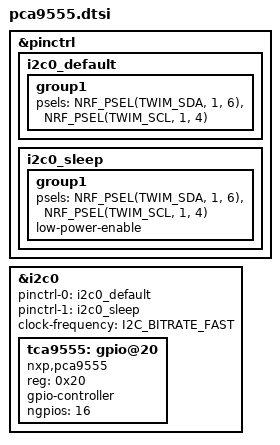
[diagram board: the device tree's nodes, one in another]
#define INPUT_EV_KEY 0x01               /**< Key event */
#define INPUT_EV_REL 0x02               /**< Relative coordinate event */
#define INPUT_EV_ABS 0x03               /**< Absolute coordinate event */
#define INPUT_EV_MSC 0x04               /**< Miscellaneous event */
#define INPUT_EV_VENDOR_START 0xf0      /**< Vendor specific event start */
#define INPUT_EV_VENDOR_STOP 0xff       /**< Vendor specific event stop */

#define INPUT_REL_X 0x00                /**< Relative X coordinate */
#define INPUT_REL_Y 0x01                /**< Relative Y coordinate */
#define INPUT_REL_WHEEL 0x08            /**< Relative wheel coordinate */
#define INPUT_REL_HWHEEL 0x06           /**< Relative horizontal wheel coordinate */
#define INPUT_REL_MISC 0x09             /**< Relative misc coordinate */

&pinctrl {
    i2c0_default: i2c0_default {
        group1 {
            psels =
                <NRF_PSEL(TWIM_SDA, 1, 6)>,
                <NRF_PSEL(TWIM_SCL, 1, 4)>;
        };
    };


    i2c0_sleep: i2c0_sleep {
        group1 {
            psels = <NRF_PSEL(TWIM_SDA, 1, 6)>,
                    <NRF_PSEL(TWIM_SCL, 1, 4)>;
            low-power-enable;
        };
    };
};


&i2c0 {
    status = "okay";

    pinctrl-0 = <&i2c0_default>;
    pinctrl-1 = <&i2c0_sleep>;
    pinctrl-names = "default", "sleep";

    clock-frequency = <I2C_BITRATE_FAST>;

    tca9555: gpio@20 {
        compatible = "nxp,pca9555";
        reg = <0x20>;

        gpio-controller;
        #gpio-cells = <2>;
        ngpios = <16>;

        //interrupt-gpios = <&gpio0 11 GPIO_ACTIVE_LOW>;
    };
};
